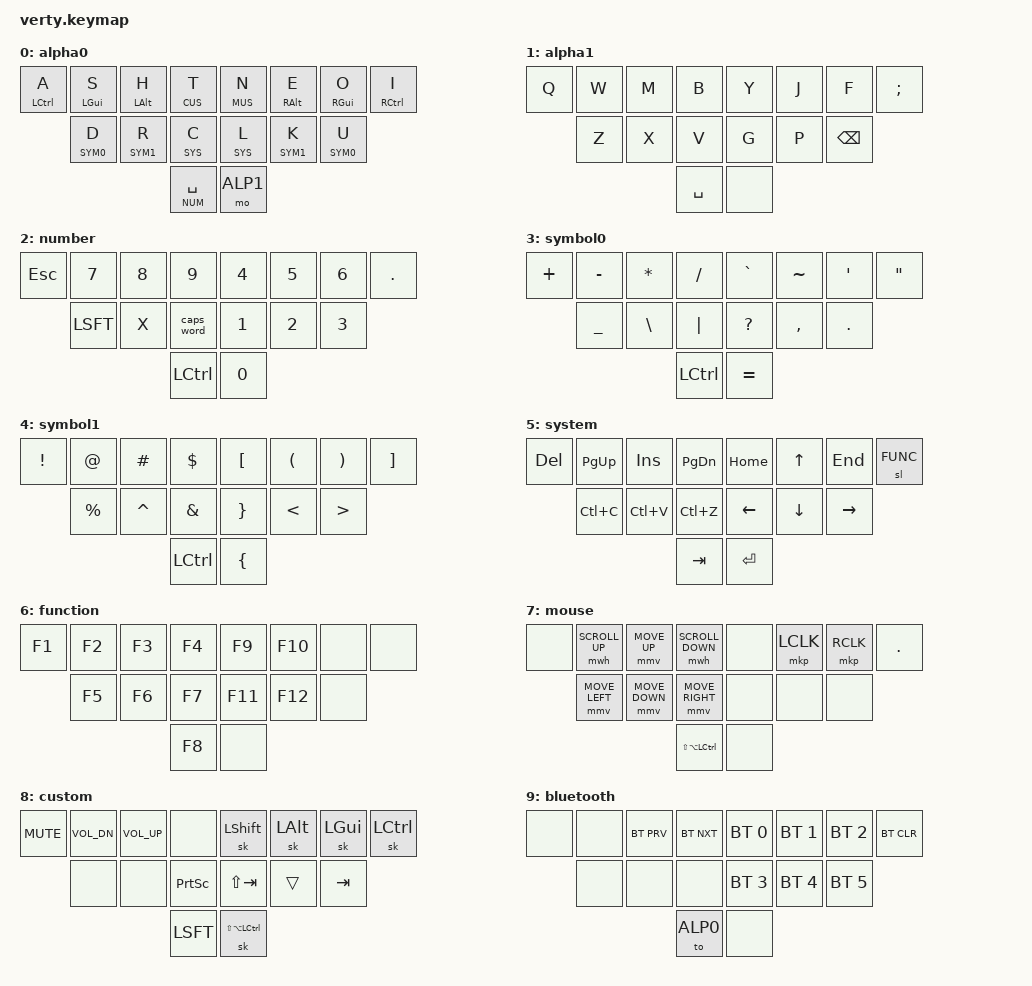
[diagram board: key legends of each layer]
#include <behaviors.dtsi>
#include <dt-bindings/zmk/keys.h>
#include <dt-bindings/zmk/bt.h>
#include <dt-bindings/zmk/mouse.h>

/* layers */
#define ALP0 0
#define ALP1 1
#define NUM  2
#define SYM0 3
#define SYM1 4
#define SYS  5
#define FUNC 6
#define MUS  7
#define CUS  8
#define BT   9

/* === mouse support setting start === */
// mouse move settings
#define U_MOUSE_MOVE_MAX 800                     /* <--- New max speed setting (default: 600) */
#undef MOVE_UP
#undef MOVE_DOWN
#undef MOVE_LEFT
#undef MOVE_RIGHT
#define MOVE_UP MOVE_VERT(-U_MOUSE_MOVE_MAX)
#define MOVE_DOWN MOVE_VERT(U_MOUSE_MOVE_MAX)
#define MOVE_LEFT MOVE_HOR(-U_MOUSE_MOVE_MAX)
#define MOVE_RIGHT MOVE_HOR(U_MOUSE_MOVE_MAX)
&mmv {
	time-to-max-speed-ms = <500>;             /* <--- How long time until max speed is reached (default: 500) */
};

// mouse wheel settings
#define U_MOUSE_SCROLL_MAX 20                    /* <--- New max speed setting (default: 10) */
#undef SCROLL_UP
#undef SCROLL_DOWN
#undef SCROLL_LEFT
#undef SCROLL_RIGHT
#define SCROLL_UP SCROLL_VERT(U_MOUSE_SCROLL_MAX)
#define SCROLL_DOWN SCROLL_VERT(-U_MOUSE_SCROLL_MAX)
#define SCROLL_LEFT SCROLL_HOR(-U_MOUSE_SCROLL_MAX)
#define SCROLL_RIGHT SCROLL_HOR(U_MOUSE_SCROLL_MAX)
&mwh {
    time-to-max-speed-ms = <500>;                 /* <--- How long time until max speed is reached */
};
/* === mouse support setting end === */

&lt {
    quick_tap_ms = <200>;
    flavor = "tap-preferred";
};
&sk {
    release-after-ms = <3000>;
    // quick-release;
};
&sl {
    release-after-ms = <2000>;
    // quick-release;
};

/ {
    combos {
        compatible = "zmk,combos";
        combo_to_bt {
            timeout-ms = <10>;
            key-positions = <2 3>;
            bindings = <&to BT>;
            layers = <SYS>;
        };
        combo_bspc {
            timeout-ms = <20>;
            key-positions = <11 12>;
            bindings = <&kp BSPC>;
            layers = <ALP0 ALP1 NUM>;
        };
        combo_caps {
            timeout-ms = <20>;
            key-positions = <4 5 6>;
            bindings = <&kp CAPS>;
            layers = <ALP0>;
        };
        combo_sk_shift {
            timeout-ms = <20>;
            key-positions = <1 2 3>;
            bindings = <&sk LSHIFT>;
            layers = <ALP0 ALP1>;
        };
        combo_key_repeat {
            timeout-ms = <20>;
            key-positions = <8 9 10>;
            bindings = <&key_repeat>;
            layers = <ALP0>;
        };
    };

    behaviors {
        tw: type_write {
            compatible = "zmk,behavior-hold-tap";
            label = "TYPE_WRITE";
            #binding-cells = <2>;
            tapping-term-ms = <200>;
            quick_tap_ms = <250>;
            bindings = <&mo>, <&kp>;
            hold-trigger-key-positions = <0 1 2 3 4 5 6 7 8 9 10 11 12 13>;
        };
        hm: homerow_mod {
            compatible = "zmk,behavior-hold-tap";
            label = "HOMEROW_MOD";
            #binding-cells = <2>;
            tapping-term-ms = <300>;
            quick_tap_ms = <250>;
            flavor = "tap-preferred";
            bindings = <&kp>, <&kp>;
        };
        hl: homerow_layer {
            compatible = "zmk,behavior-hold-tap";
            label = "HOMEROW_LAYER";
            #binding-cells = <2>;
            tapping-term-ms = <220>;
            quick_tap_ms = <250>;
            flavor = "tap-preferred";
            bindings = <&mo>, <&kp>;
        };
    };

    keymap {
        compatible = "zmk,keymap";

        alpha0 {
            bindings = <
            &hm LCTL A      &hm LGUI S      &hm LALT H      &hl CUS T       &hl MUS N       &hm RALT E      &hm RGUI O     &hm RCTL I
                            &hl SYM0 D      &hl SYM1 R      &hl SYS C       &hl SYS L       &hl SYM1 K      &hl SYM0 U
                                                            &lt NUM SPC     &mo ALP1
            >;
        };

        alpha1 {
            bindings = <
            &kp Q           &kp W           &kp M           &kp B           &kp Y           &kp J           &kp F         &kp SEMI
                            &kp Z           &kp X           &kp V           &kp G           &kp P           &kp BSPC
                                                            &kp SPC         &none
            >;
        };

        number {
            bindings = <
            &kp ESC         &kp N7          &kp N8          &kp N9          &kp N4          &kp N5          &kp N6          &kp DOT
                            &kp LSFT        &kp X           &caps_word      &kp N1          &kp N2          &kp N3
                                                            &kp LCTRL       &kp N0
            >;
        };

        symbol0 {
            bindings = <
            &kp PLUS        &kp MINUS       &kp STAR        &kp FSLH        &kp GRAVE       &kp TILDE       &kp SQT         &kp DQT
                            &kp UNDER       &kp BSLH        &kp PIPE        &kp QMARK       &kp COMMA       &kp DOT
                                                            &kp LCTRL       &kp EQUAL
            >;
        };

        symbol1 {
            bindings = <
            &kp EXCL        &kp AT          &kp HASH        &kp DLLR        &kp LBKT        &kp LPAR        &kp RPAR        &kp RBKT
                            &kp PRCNT       &kp CARET       &kp AMPS        &kp RBRC        &kp LT          &kp GT
                                                            &kp LCTRL       &kp LBRC
            >;
        };

        system {
            bindings = <
            &kp DEL         &kp PG_UP       &kp INS         &kp PG_DN       &kp HOME        &kp UP          &kp END         &sl FUNC
                            &kp LC(C)       &kp LC(V)       &kp LC(Z)       &kp LEFT        &kp DOWN        &kp RIGHT
                                                            &kp TAB         &kp ENTER
            >;
        };

        function {
            bindings = <
            &kp F1          &kp F2          &kp F3          &kp F4          &kp F9          &kp F10         &none           &none
                            &kp F5          &kp F6          &kp F7          &kp F11         &kp F12         &none
                                                            &kp F8          &none
            >;
        };

        mouse {
            bindings = <
            &none           &mwh SCROLL_UP  &mmv MOVE_UP    &mwh SCROLL_DOWN &none           &mkp LCLK       &mkp RCLK       &kp DOT
                            &mmv MOVE_LEFT  &mmv MOVE_DOWN  &mmv MOVE_RIGHT  &none           &none           &none
                                                            &kp LS(LA(LCTRL))   &none
            >;
        };

        custom {
            bindings = <
            &kp C_MUTE      &kp C_VOL_DN    &kp C_VOL_UP    &none           &sk LSHIFT      &sk LALT        &sk LGUI        &sk LCTRL
                            &none           &none           &kp PSCRN       &kp LS(TAB)     &trans          &kp TAB
                                                            &kp LSFT        &sk LS(LA(LCTRL))
            >;
        };

        bluetooth {
            bindings = <
            &none           &none           &bt BT_PRV      &bt BT_NXT      &bt BT_SEL 0    &bt BT_SEL 1    &bt BT_SEL 2    &bt BT_CLR
                            &none           &none           &none           &bt BT_SEL 3    &bt BT_SEL 4    &bt BT_SEL 5
                                                            &to ALP0        &none
            >;
        };
    };
};

